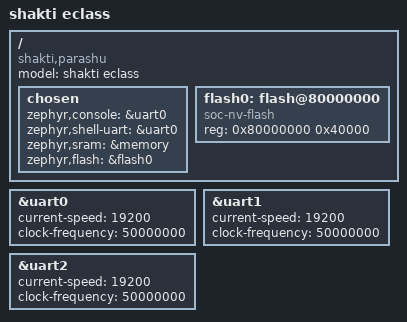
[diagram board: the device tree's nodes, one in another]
/dts-v1/;

#include <riscv32-parashu.dtsi>

/ {
	model = "shakti eclass";
	compatible = "shakti,parashu";

chosen {
		zephyr,console = &uart0;
		zephyr,shell-uart = &uart0;
		zephyr,sram = &memory;
        zephyr,flash = &flash0;
	};



		flash0: flash@80000000 {
			compatible = "soc-nv-flash";
			reg = <0x80000000 0x40000>;
		};


};


&uart0 {
	status = "ok";
	current-speed = <19200>;
	clock-frequency = <50000000>;
};

&uart1 {
	status = "ok";
	current-speed = <19200>;
	clock-frequency = <50000000>;
};

&uart2 {
	status = "ok";
	current-speed = <19200>;
	clock-frequency = <50000000>;
};
